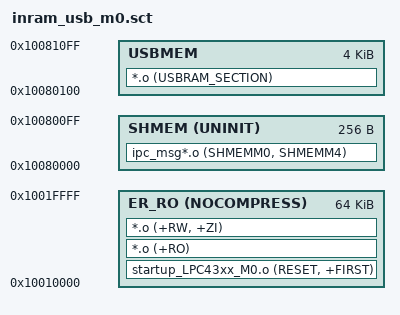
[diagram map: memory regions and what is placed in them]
;-------------------------------------------------------------------------------------
;   Keil scatter loading file
;-------------------------------------------------------------------------------------

; IRAM loaded image at offset 64K with size 32K max
; All code and data on the M0 core has a total size <= 32K
; Using this address, the code will load and run embeeded in the M4 image
; without an additional copy and it will load and run via the debugger on
; attached to the M0 core.
FLASH 0x10010000 0x10000 {
  ; All M0 code and RO data in IRAM at address 0x10010000. The image is linked
  ; here, so when the image is inserted in the M4 image, it must be guaranteed
  ; this location in the M4 image. See the M4 image's linker script to see how
  ; this is done.
  ; Note the M0 image must reside on a 4K boundary
  ; Note the use of the NOCOMPRESS attribute. This will allow the data section
  ; to be uncompressed in the image. If the section is compressed, the M0 data
  ; section may overlap with M4 data once it's uncompressed.
  ER_RO 0x10010000 NOCOMPRESS 0x10000 {
    startup_LPC43xx_M0.o (RESET, +FIRST)
    *.o (+RO)
    *.o (+RW, +ZI)
  }

  ; Shared memory region for M0 and M4 core. The M4 core initializes this
  ; region at run-time usually before the M0 core is running. The UNINIT
  ; attribute is used so the M0 core doesn't try to re-initialize the data
  ; region and instead uses what the M4 core already initialized.
  SHMEM 0x10080000 UNINIT 0x100 {
	ipc_msg*.o (SHMEMM0, SHMEMM4)
  }

  ; Memory used by nxpUSBLib stack
  USBMEM 0x10080100 0x1000 {
	*.o (USBRAM_SECTION)
  }
}
